# D1H.pdf register map
Vendor: Allwinner; Series: D1H.pdf; File version: 0.1
CPU: XuanTie C906 RISC-V CPU 0, little endian, MPU, FPU, double-precision FPU, 0 interrupt priority bits
Registers are 32-bit, read-write, reset 0x0 unless marked. A register's access mark holds for its fields unless they carry their own. Offsets are from the block's base; [hi:lo] are bit positions.

## CIR_RX
Base 0x07040000
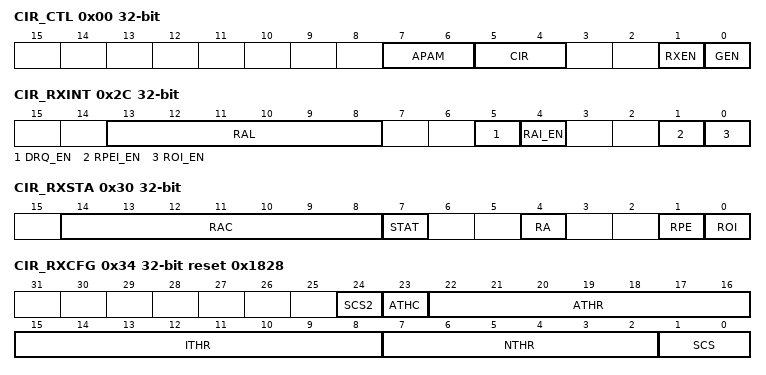
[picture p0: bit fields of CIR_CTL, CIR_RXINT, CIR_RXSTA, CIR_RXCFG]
0x00 CIR_CTL — CIR Control Register
  [7:6] APAM — Active Pulse Accept Mode 00, 01: Both positive and negative pulses are valid as a leading code 10: Only negative pulse is valid as a leading code 11: Only positive pulse is valid as a leading code
    2=Only negative pulse is valid as a leading code; 3=Only positive pulse is valid as a leading code
  [5:4] CIR — ENABLE 00~10: Reserved 11: CIR mode enable
    3=mode (CIR mode enable)
  [1] RXEN — Receiver Block Enable 0: Disable 1: Enable
    0=Disable; 1=Enable
  [0] GEN — Global Enable A disable on this bit overrides any other block or channel enables and flushes all FIFOs. 0: Disable 1: Enable
    0=Disable; 1=Enable
0x10 CIR_RXPCFG reset 0x4 — CIR Receiver Pulse Configure Register
  [2] RPPI — Receiver Pulse Polarity Invert 0: Do not invert receiver signal 1: Invert receiver signal
    0=Do not invert receiver signal; 1=Invert receiver signal
0x20 CIR_RXFIFO — CIR Receiver FIFO Register
  [7:0] RBF ro — Receiver Byte FIFO
0x2C CIR_RXINT — CIR Receiver Interrupt Control Register
  [13:8] RAL — RX FIFO available received byte level for interrupt and DMA request TRIGGER_LEVEL = RAL + 1
  [5] DRQ_EN — RX FIFO DMA Enable 0: Disable 1: Enable When it is set to ‘1’, the Receiver FIFO DRQ is asserted if reaching RAL. The DRQ is de-asserted when the condition fails.
    0=Disable; 1=Enable When it is set to ‘1’, the Receiver FIFO DRQ is asserted if reaching RAL. The DRQ is de-asserted when the condition fails.
  [4] RAI_EN — RX FIFO Available Interrupt Enable 0: Disable 1: Enable When it is set to ‘1’, the Receiver FIFO IRQ is asserted if reaching RAL. The IRQ is de-asserted when the condition fails.
    0=Disable; 1=Enable When it is set to ‘1’, the Receiver FIFO IRQ is asserted if reaching RAL. The IRQ is de-asserted when the condition fails.
  [1] RPEI_EN — Receiver Packet End Interrupt Enable 0: Disable 1: Enable
    0=Disable; 1=Enable
  [0] ROI_EN — Receiver FIFO Overrun Interrupt Enable 0: Disable 1: Enable
    0=Disable; 1=Enable
0x30 CIR_RXSTA — CIR Receiver Status Register
  [14:8] RAC ro — RX FIFO Available Counter 0: No available data in RX FIFO 1: 1-byte available data in RX FIFO 2: 2-bytes available data in RX FIFO … 64: 64-bytes available data in RX FIFO
    2=2-bytes available data in RX FIFO …; 64=64-bytes available data in RX FIFO
  [7] STAT ro — Status of CIR 0: Idle 1: Busy
    0=Idle; 1=Busy
  [4] RA write-1-clears — RX FIFO Available 0: RX FIFO not available according to its level 1: RX FIFO available according to its level Writing 1 clears this bit.
    0=RX_FIFO (RX FIFO not available according to its level); 1=RX FIFO available according to its level Writing 1 clears this bit
  [1] RPE write-1-clears — Receiver Packet End Flag 0: STO was not detected. In CIR mode, one CIR symbol is receiving or not detected. 1: STO field or packet abort symbol (7’b0000,000 and 8’b0000,0000 for MIR and FIR) is detected. In CIR mode, one CIR symbol is received. Writing 1 clears this bit.
    0=STO was not detected. In CIR mode, one CIR symbol is receiving or not detected.; 1=STO field or packet abort symbol (7’b0000,000 and 8’b0000,0000 for MIR and FIR) is detected. In CIR mode, one CIR symbol is received. Writing 1 clears this bit.
  [0] ROI write-1-clears — Receiver FIFO Overrun 0: Receiver FIFO not overrun 1: Receiver FIFO overrun Writing 1 clears this bit.
    0=Receiver_FIFO_not_overrun; 1=Receiver FIFO overrun Writing 1 clears this bit
0x34 CIR_RXCFG reset 0x1828 — CIR Receiver Configure Register
  [24] SCS2 — Bit2 of Sample Clock Select for CIR This bit is defined by SCS bits below.
  [23] ATHC — Active Threshold Control for CIR 0: ATHR in a unit of (Sample Clock) 1: ATHR in a unit of (128*Sample Clocks)
    0=ATHR_in_a_unit_of__openingparen_Sample (ATHR in a unit of (Sample Clock)); 1=ATHR_in_a_unit_of__openingparen_128_times_Sample (ATHR in a unit of (128*Sample Clocks))
  [22:16] ATHR — Active Threshold for CIR These bits control the duration of CIR from the idle to the active state. The duration can be calculated by ((ATHR + 1)*(ATHC? Sample Clock: 128*Sample Clock)).
  [15:8] ITHR — Idle Threshold for CIR The Receiver uses it to decide whether the CIR command is received. If there is no CIR signal on the air, the receiver is staying in IDLE status. One active pulse will bring the receiver from IDLE status to Receiving status. After the CIR receiver ends, the inputting signal will keep the specified level (high or low level) for a long time. The receiver can use this idle signal duration to decide that it has received the CIR command. The corresponding flag is asserted. If the corresponding interrupt is enabled, the interrupt line is asserted to the CPU. When the duration of the signal keeps one status (high or low level) for the specified duration ((ITHR + 1)*128 sample_clk), this means that the previous CIR command is finished.
  [7:2] NTHR — Noise Threshold for CIR When the duration of the signal pulse (high or low level) is less than NTHR, the pulse is taken as noise and should be discarded by hardware. 0: All samples are recorded into RX FIFO 1: If the signal is only one sample duration, it is taken as noise and discarded. 2: If the signal is less than (<=) two sample duration, it is taken as noise and discarded. … 61: If the signal is less than (<=) sixty-one sample duration, it is taken as noise and discarded.
  [1:0] SCS — Sample Clock Select for CIR SCS2 SCS[1] SCS[0] Sample Clock 0 0 0 CIR_CLK/64 0 0 1 CIR_CLK/128 0 1 0 CIR_CLK/256 0 1 1 CIR_CLK/512 1 0 0 CIR_CLK 1 0 1 Reserved 1 1 0 Reserved 1 1 1 Reserved
